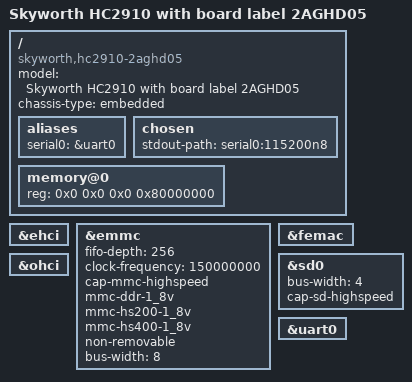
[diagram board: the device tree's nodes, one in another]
// SPDX-License-Identifier: GPL-2.0
/*
 * DTS File for Skyworth HC2910 with board label 2AGHD05 set-top box.
 *
 * Released under the GPLv2 only.
 */

/dts-v1/;

#include "hi3798mv200.dtsi"

/ {
	// Usually known as Henan Guangdian HC2910
	model = "Skyworth HC2910 with board label 2AGHD05";
	compatible = "skyworth,hc2910-2aghd05", "hisilicon,hi3798mv200";
	chassis-type = "embedded";

	aliases {
		serial0 = &uart0;
	};

	chosen {
		stdout-path = "serial0:115200n8";
	};

	memory@0 {
		device_type = "memory";
		reg = <0x0 0x0 0x0 0x80000000>;
	};
};

&ehci {
	status = "okay";
};

&emmc {
	fifo-depth = <256>;
	// The downstream driver said that the maximum frequency is limited to
	// 150MHz for HS400
	clock-frequency = <150000000>;
	cap-mmc-highspeed;
	mmc-ddr-1_8v;
	mmc-hs200-1_8v;
	mmc-hs400-1_8v;
	non-removable;
	bus-width = <8>;
	status = "okay";
};

&femac {
	status = "okay";
};

&ohci {
	status = "okay";
};

&sd0 {
	bus-width = <4>;
	cap-sd-highspeed;
	status = "okay";
};

&uart0 {
	status = "okay";
};
